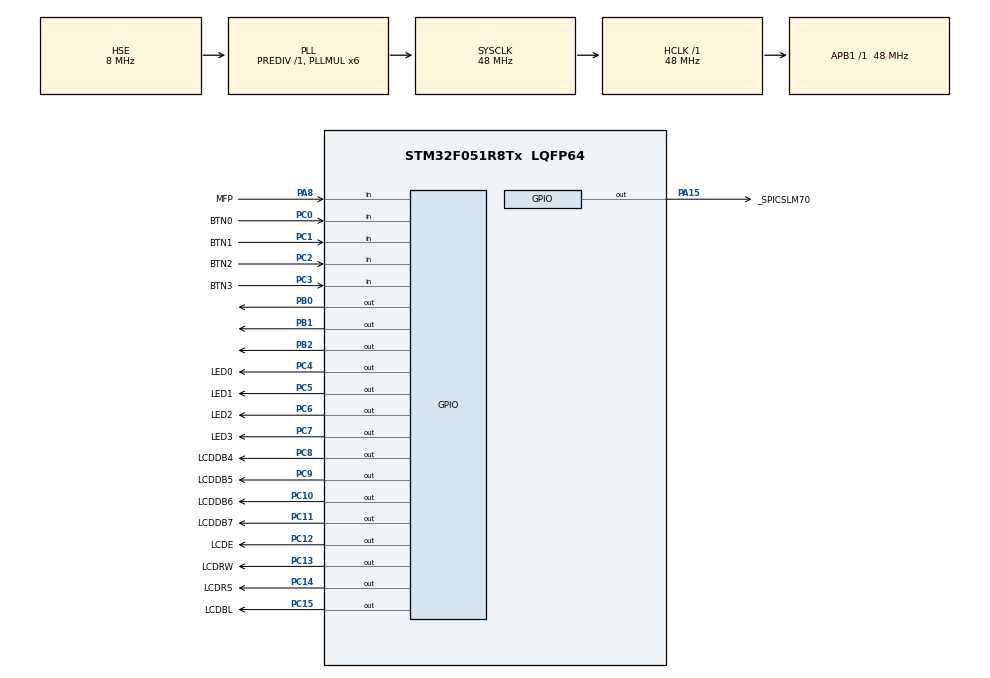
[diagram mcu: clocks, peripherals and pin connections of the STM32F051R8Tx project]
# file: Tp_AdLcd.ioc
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Mcu.Family=STM32F0
Mcu.Name=STM32F051R8Tx
Mcu.Package=LQFP64
NVIC.TIM6_DAC_IRQn=true\:0\:0\:false\:false\:true\:true\:true
PA0.GPIO_Label=AI0
PA0.Signal=ADC_IN0
PA10.GPIO_Label=USART1RX
PA10.Signal=USART1_RX
PA11.GPIO_Label=USART1CTS
PA11.Signal=USART1_CTS
PA12.GPIO_Label=USART1RTS
PA12.Signal=USART1_RTS
PA13.Mode=Serial_Wire
PA13.Signal=SYS_SWDIO
PA14.Mode=Serial_Wire
PA14.Signal=SYS_SWCLK
PA15.GPIO_Label=_SPICSLM70
PA15.PinState=GPIO_PIN_SET
PA15.Signal=GPIO_Output
PA5.GPIO_Label=SPISCK
PA5.Signal=SPI1_SCK
PA6.GPIO_Label=SPIMISO
PA6.Signal=SPI1_MISO
PA7.GPIO_Label=SPIMOSI
PA7.Signal=SPI1_MOSI
PA8.GPIO_Label=MFP
PA8.Signal=GPIO_Input
PA9.GPIO_Label=USART1TX
PA9.Signal=USART1_TX
PB0.Signal=GPIO_Output
PB1.Signal=GPIO_Output
PB2.Signal=GPIO_Output
PC0.GPIO_Label=BTN0
PC0.Signal=GPIO_Input
PC1.GPIO_Label=BTN1
PC1.Signal=GPIO_Input
PC10.GPIO_Label=LCDDB6
PC10.Signal=GPIO_Output
PC11.GPIO_Label=LCDDB7
PC11.Signal=GPIO_Output
PC12.GPIO_Label=LCDE
PC12.Signal=GPIO_Output
PC13.GPIO_Label=LCDRW
PC13.Signal=GPIO_Output
PC14-OSC32_IN.GPIO_Label=LCDRS
PC14-OSC32_IN.Signal=GPIO_Output
PC15-OSC32_OUT.GPIO_Label=LCDBL
PC15-OSC32_OUT.Signal=GPIO_Output
PC2.GPIO_Label=BTN2
PC2.Signal=GPIO_Input
PC3.GPIO_Label=BTN3
PC3.Signal=GPIO_Input
PC4.GPIO_Label=LED0
PC4.PinState=GPIO_PIN_SET
PC4.Signal=GPIO_Output
PC5.GPIO_Label=LED1
PC5.PinState=GPIO_PIN_SET
PC5.Signal=GPIO_Output
PC6.GPIO_Label=LED2
PC6.PinState=GPIO_PIN_SET
PC6.Signal=GPIO_Output
PC7.GPIO_Label=LED3
PC7.PinState=GPIO_PIN_SET
PC7.Signal=GPIO_Output
PC8.GPIO_Label=LCDDB4
PC8.Signal=GPIO_Output
PC9.GPIO_Label=LCDDB5
PC9.Signal=GPIO_Output
PF0-OSC_IN.GPIO_Label=OSCIN
PF0-OSC_IN.Mode=HSE-External-Oscillator
PF0-OSC_IN.Signal=RCC_OSC_IN
PF1-OSC_OUT.GPIO_Label=OSCOUT
PF1-OSC_OUT.Mode=HSE-External-Oscillator
PF1-OSC_OUT.Signal=RCC_OSC_OUT
PF6.Signal=I2C2_SCL
PF7.Signal=I2C2_SDA
ProjectManager.HeapSize=0x200
ProjectManager.StackSize=0x400
ProjectManager.TargetToolchain=MDK-ARM V5
RCC.AHBFreq_Value=48000000
RCC.APB1Freq_Value=48000000
RCC.APB1TimFreq_Value=48000000
RCC.EnbaleCSS=true
RCC.HCLKFreq_Value=48000000
RCC.PLLMUL=RCC_PLL_MUL6
RCC.PLLSourceVirtual=RCC_PLLSOURCE_HSE
RCC.SYSCLKFreq_VALUE=48000000
RCC.SYSCLKSource=RCC_SYSCLKSOURCE_PLLCLK
VP_TIM6_VS_ClockSourceINT.Mode=Enable_Timer
board=test01_blink

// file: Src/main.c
/* USER CODE BEGIN Header */
/**
  ******************************************************************************
  * @file           : main.c
  * @brief          : Main program body
  ******************************************************************************
  * @attention
  *
  * <h2><center>&copy; Copyright (c) 2020 STMicroelectronics.
  * All rights reserved.</center></h2>
  *
  * This software component is licensed by ST under BSD 3-Clause license,
  * the "License"; You may not use this file except in compliance with the
  * License. You may obtain a copy of the License at:
  *                        opensource.org/licenses/BSD-3-Clause
  *
  ******************************************************************************
  */
/* USER CODE END Header */
#include "main.h"
#include "tim.h"
#include "gpio.h"

/* USER CODE BEGIN Includes */

#include "17400.h"
#include "stm32delays.h"
#include "stm32driverlcd.h"

/* USER CODE END Includes */

void SystemClock_Config(void);

/* USER CODE BEGIN 0 */

// ----------------------------------------------------------------
// Conversion tension de LSB en mV. Utilise la variable globale "valVref_mV"
// 0 -> 0 mV
// 4095 -> 3300 mV
uint16_t ConvAdcMilliVolt(uint16_t nLsb)
{
	// *** A COMPLETER ! ***
}

// ----------------------------------------------------------------
// Conversion de mV en chaine de caractères (ou structure) exprimée
// en V sur nDigits digits. Prévu pour tension entre 0 et 3,3V (=> u_mV entre 0 et 3300).
// La sortie contiendra donc unité + évt point décimal, dixièmes, centièmes, millièmes,
//  selon le nb de digits demandés.
void ConvMilliVoltVolt(uint16_t u_mV, uint8_t nDigits, char* str_V /* *** OU STRUCTURE *** */)
{
	// *** A COMPLETER ! ***
}

// ----------------------------------------------------------------
// *** ADC ***

// Lecture d'un canal AD par polling
// Il faut auparavant avoir configuré la/les pin(s) concernée(s) en entrée analogique
uint16_t Adc_read(uint8_t chNr)
{
	// *** A COMPLETER ! ***
}

// ----------------------------------------------------------------

/* USER CODE END 0 */

int main(void)
{
  /* USER CODE BEGIN 1 */
	//variables
	// *** A COMPLETER ! ***

	//init
	// *** A COMPLETER ! ***

  /* USER CODE END 1 */

  /* MCU Configuration--------------------------------------------------------*/

  /* Reset of all peripherals, Initializes the Flash interface and the Systick. */
  HAL_Init();

  /* Configure the system clock */
  SystemClock_Config();

  /* Initialize all configured peripherals */
  MX_GPIO_Init();
  MX_TIM6_Init();

  /* Infinite loop */
  while (1)
  {

    /* USER CODE BEGIN 3 */

		// *** A COMPLETER ! ***

  }
  /* USER CODE END 3 */
}

void SystemClock_Config(void)
{
  RCC_OscInitTypeDef RCC_OscInitStruct = {0};
  RCC_ClkInitTypeDef RCC_ClkInitStruct = {0};

  /** Initializes the RCC Oscillators according to the specified parameters
  * in the RCC_OscInitTypeDef structure.
  */
  RCC_OscInitStruct.OscillatorType = RCC_OSCILLATORTYPE_HSE;
  RCC_OscInitStruct.HSEState = RCC_HSE_ON;
  RCC_OscInitStruct.PLL.PLLState = RCC_PLL_ON;
  RCC_OscInitStruct.PLL.PLLSource = RCC_PLLSOURCE_HSE;
  RCC_OscInitStruct.PLL.PLLMUL = RCC_PLL_MUL6;
  RCC_OscInitStruct.PLL.PREDIV = RCC_PREDIV_DIV1;
  if (HAL_RCC_OscConfig(&RCC_OscInitStruct) != HAL_OK)
  {
    Error_Handler();
  }
  /** Initializes the CPU, AHB and APB buses clocks
  */
  RCC_ClkInitStruct.ClockType = RCC_CLOCKTYPE_HCLK|RCC_CLOCKTYPE_SYSCLK
                              |RCC_CLOCKTYPE_PCLK1;
  RCC_ClkInitStruct.SYSCLKSource = RCC_SYSCLKSOURCE_PLLCLK;
  RCC_ClkInitStruct.AHBCLKDivider = RCC_SYSCLK_DIV1;
  RCC_ClkInitStruct.APB1CLKDivider = RCC_HCLK_DIV1;

  if (HAL_RCC_ClockConfig(&RCC_ClkInitStruct, FLASH_LATENCY_1) != HAL_OK)
  {
    Error_Handler();
  }
  /** Enables the Clock Security System
  */
  HAL_RCC_EnableCSS();
}

void Error_Handler(void)
{
}

/************************ (C) COPYRIGHT STMicroelectronics *****END OF FILE****/
